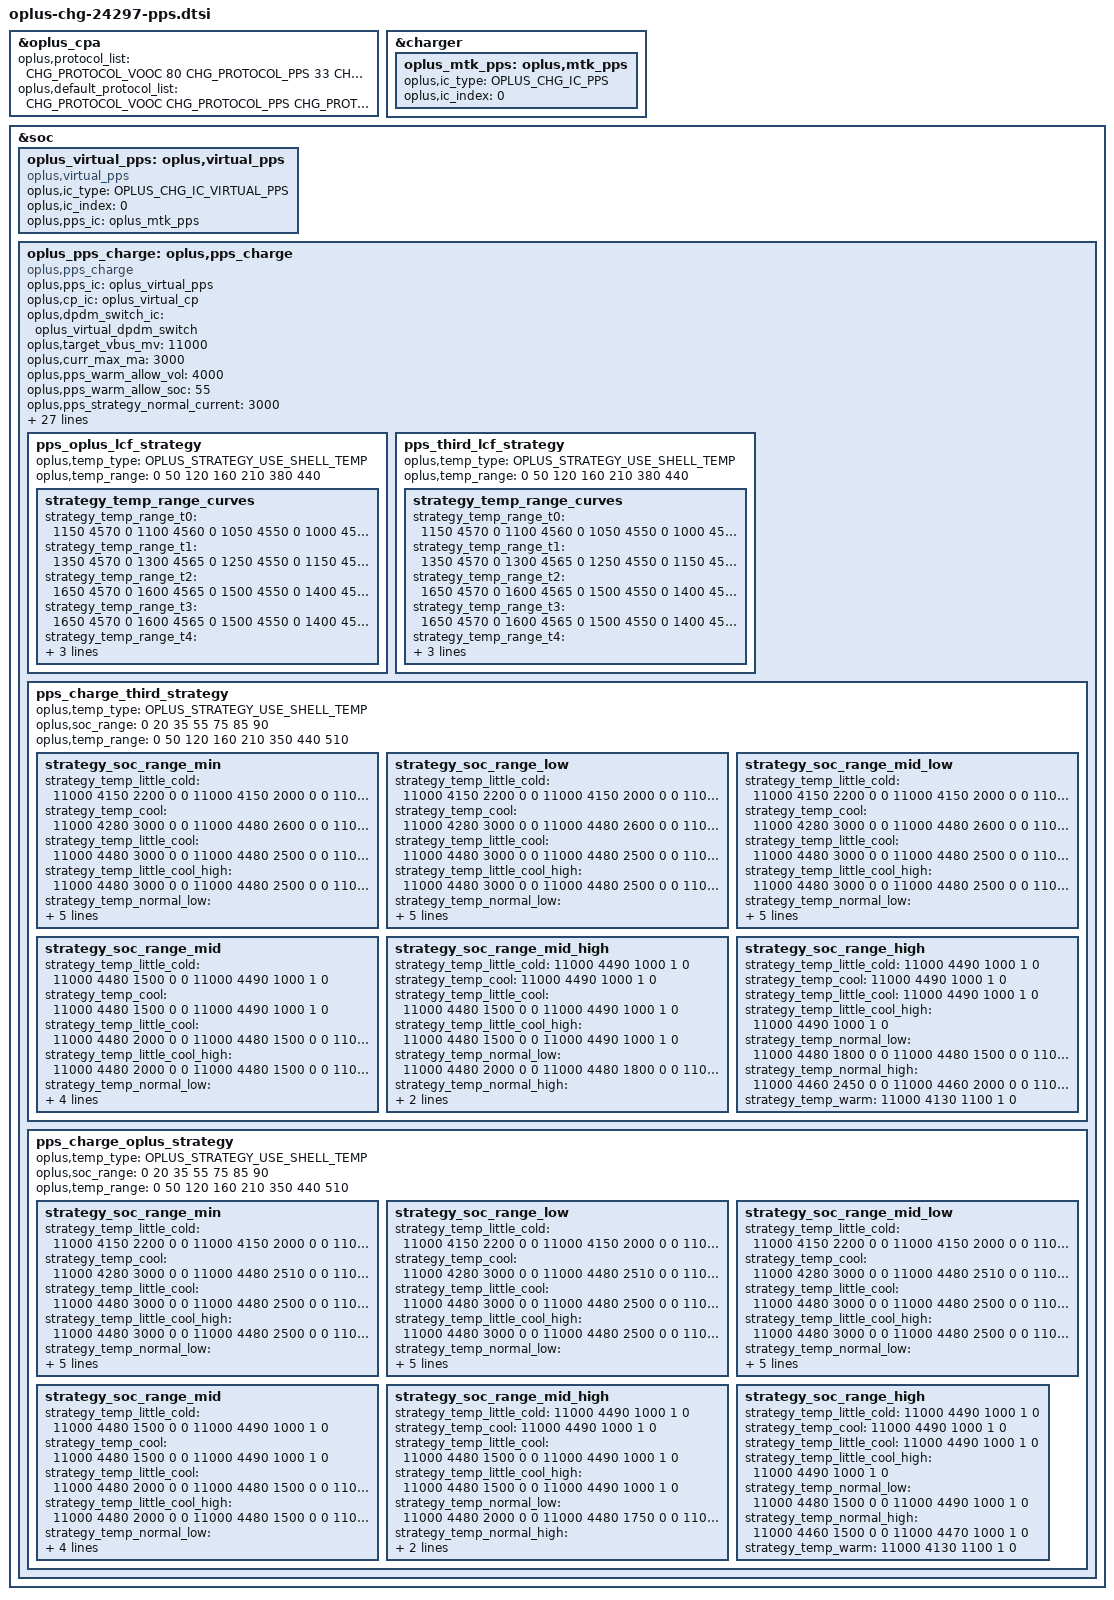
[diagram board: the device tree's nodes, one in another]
//ifdef OPLUS_FEATURE_CHG_BASIC
&oplus_cpa {
	oplus,protocol_list = <CHG_PROTOCOL_VOOC 80
			       CHG_PROTOCOL_PPS 33
			       CHG_PROTOCOL_PD 18
			       CHG_PROTOCOL_QC 18>;
	oplus,default_protocol_list = <CHG_PROTOCOL_VOOC
				       CHG_PROTOCOL_PPS
				       CHG_PROTOCOL_PD>;
};

&charger {
	oplus_mtk_pps: oplus,mtk_pps {
		oplus,ic_type = <OPLUS_CHG_IC_PPS>;
		oplus,ic_index = <0>;
	};
};
&soc {
	oplus_virtual_pps: oplus,virtual_pps {
		compatible = "oplus,virtual_pps";

		oplus,ic_type = <OPLUS_CHG_IC_VIRTUAL_PPS>;
		oplus,ic_index = <0>;
		oplus,pps_ic = <&oplus_mtk_pps>;
	};
	oplus_pps_charge: oplus,pps_charge {
		compatible = "oplus,pps_charge";
		oplus,pps_ic = <&oplus_virtual_pps>;
		oplus,cp_ic = <&oplus_virtual_cp>;
		oplus,dpdm_switch_ic = <&oplus_virtual_dpdm_switch>;

		oplus,target_vbus_mv = <11000>;
		oplus,curr_max_ma = <3000>;

		oplus,pps_warm_allow_vol = <4000>;
		oplus,pps_warm_allow_soc = <55>;
		oplus,pps_strategy_normal_current = <3000>;
		oplus,pps_over_high_or_low_current = <3000>;
		oplus,pps_timeout_third = <17563>;
		oplus,pps_timeout_oplus = <17563>;
		oplus,pps_ibat_over_third = <7400>;
		oplus,pps_ibat_over_oplus = <7400>;
		oplus,pps_full_cool_sw_vbat = <4490>;
		oplus,pps_full_normal_sw_vbat = <4490>;
		oplus,pps_full_normal_hw_vbat = <4500>;
		oplus,pps_full_ffc_vbat = <4500>;
		oplus,pps_full_warm_vbat = <4130>;
		oplus,pps_full_cool_sw_vbat_third = <4490>;
		oplus,pps_full_normal_sw_vbat_third= <4490>;
		oplus,pps_full_normal_hw_vbat_third = <4500>;
		oplus,pps_current_change_timeout = <100>;
		oplus,curve_strategy_name = "pps_ufcs_curve_v2";
		oplus,pps_strategy_batt_high_temp = <410 420 430 400 410 420>;
		oplus,pps_strategy_high_current = <3000 2000 2000 3000 3000 3000>;
		oplus,pps_little_cool_high_temp = <210>;
		oplus,pps_charge_strategy_soc = <0 20 35 55 75 85 90>;
		oplus,pps_charge_strategy_temp = <0 50 120 160 350 440 530>;

		oplus,plc_strategy-data = <&cp_2t1_simple_strategy>;
		oplus,plc_strategy-names = "default";

		pps_oplus_lcf_strategy {
			oplus,temp_type = <OPLUS_STRATEGY_USE_SHELL_TEMP>;
			oplus,temp_range = <0 50 120 160 210 380 440>;

			strategy_temp_range_curves {
				strategy_temp_range_t0 =	<1150 4570 0
								 1100 4560 0
								 1050 4550 0
								 1000 4540 0
								 950 4530 1>;
				strategy_temp_range_t1 =	<1350 4570 0
								 1300 4565 0
								 1250 4550 0
								 1150 4540 0
								 1050 4530 1>;
				strategy_temp_range_t2 =	<1650 4570 0
								 1600 4565 0
								 1500 4550 0
								 1400 4540 0
								 1250 4530 1>;
				strategy_temp_range_t3 =	<1650 4570 0
								 1600 4565 0
								 1500 4550 0
								 1400 4540 0
								 1250 4530 1>;
				strategy_temp_range_t4 =	<3250 4550 0
								 3000 4520 0
								 2300 4520 0
								 1600 4500 0
								 1000 4480 1>;
				strategy_temp_range_t5 =	<4600 4534 0
								 4300 4520 0
								 3200 4500 0
								 2100 4480 0
								 1000 4470 1>;
			};
		};

		pps_third_lcf_strategy {
			oplus,temp_type = <OPLUS_STRATEGY_USE_SHELL_TEMP>;
			oplus,temp_range = <0 50 120 160 210 380 440>;

			strategy_temp_range_curves {
				strategy_temp_range_t0 =	<1150 4570 0
								 1100 4560 0
								 1050 4550 0
								 1000 4540 0
								 950 4530 1>;
				strategy_temp_range_t1 =	<1350 4570 0
								 1300 4565 0
								 1250 4550 0
								 1150 4540 0
								 1050 4530 1>;
				strategy_temp_range_t2 =	<1650 4570 0
								 1600 4565 0
								 1500 4550 0
								 1400 4540 0
								 1250 4530 1>;
				strategy_temp_range_t3 =	<1650 4570 0
								 1600 4565 0
								 1500 4550 0
								 1400 4540 0
								 1250 4530 1>;
				strategy_temp_range_t4 =	<3250 4550 0
								 3000 4520 0
								 2300 4520 0
								 1600 4500 0
								 1000 4480 1>;
				strategy_temp_range_t5 =	<4600 4534 0
								 4300 4520 0
								 3200 4500 0
								 2100 4480 0
								 1000 4470 1>;
			};
		};

		pps_charge_third_strategy {
			oplus,temp_type = <OPLUS_STRATEGY_USE_SHELL_TEMP>;
			oplus,soc_range = <0 20 35 55 75 85 90>;
			oplus,temp_range = <0 50 120 160 210 350 440 510>;

			strategy_soc_range_min {
				strategy_temp_little_cold =	<11000 4150 2200 0 0
								11000 4150 2000 0 0
								11000 4480 1550 0 0
								11000 4480 1500 0 0
								11000 4490 1000 1 0>;
				strategy_temp_cool =		<11000 4280 3000 0 0
								11000 4480 2600 0 0
								11000 4480 2500 0 0
								11000 4480 2000 0 0
								11000 4480 1500 0 0
								11000 4490 1000 1 0>;
				strategy_temp_little_cool =	<11000 4480 3000 0 0
								11000 4480 2500 0 0
								11000 4480 2000 0 0
								11000 4480 1500 0 0
								11000 4490 1000 1 0>;
				strategy_temp_little_cool_high =	<11000 4480 3000 0 0
								11000 4480 2500 0 0
								11000 4480 2000 0 0
								11000 4480 1500 0 0
								11000 4490 1000 1 0>;
				strategy_temp_normal_low =	<11000 4480 3000 0 0
								11000 4480 2500 0 0
								11000 4480 2000 0 0
								11000 4480 1800 0 0
								11000 4480 1500 0 0
								11000 4490 1000 1 0>;
				strategy_temp_normal_high =	<11000 4460 3000 0 0
								11000 4460 2500 0 0
								11000 4460 2450 0 0
								11000 4460 2000 0 0
								11000 4460 1500 0 0
								11000 4470 1000 1 0>;
				strategy_temp_warm =		<11000 4120 1850 0 0
								11000 4120 1500 0 0
								11000 4130 1000 1 0>;
			};
			strategy_soc_range_low {
				strategy_temp_little_cold =	<11000 4150 2200 0 0
								11000 4150 2000 0 0
								11000 4480 1550 0 0
								11000 4480 1500 0 0
								11000 4490 1000 1 0>;
				strategy_temp_cool =		<11000 4280 3000 0 0
								11000 4480 2600 0 0
								11000 4480 2500 0 0
								11000 4480 2000 0 0
								11000 4480 1500 0 0
								11000 4490 1000 1 0>;
				strategy_temp_little_cool =	<11000 4480 3000 0 0
								11000 4480 2500 0 0
								11000 4480 2000 0 0
								11000 4480 1500 0 0
								11000 4490 1000 1 0>;
				strategy_temp_little_cool_high =	<11000 4480 3000 0 0
								11000 4480 2500 0 0
								11000 4480 2000 0 0
								11000 4480 1500 0 0
								11000 4490 1000 1 0>;
				strategy_temp_normal_low =	<11000 4480 3000 0 0
								11000 4480 2500 0 0
								11000 4480 2000 0 0
								11000 4480 1800 0 0
								11000 4480 1500 0 0
								11000 4490 1000 1 0>;
				strategy_temp_normal_high =	<11000 4460 3000 0 0
								11000 4460 2500 0 0
								11000 4460 2450 0 0
								11000 4460 2000 0 0
								11000 4460 1500 0 0
								11000 4470 1000 1 0>;
				strategy_temp_warm =		<11000 4120 1850 0 0
								11000 4120 1500 0 0
								11000 4130 1000 1 0>;
			};
			strategy_soc_range_mid_low {
				strategy_temp_little_cold =	<11000 4150 2200 0 0
								11000 4150 2000 0 0
								11000 4480 1550 0 0
								11000 4480 1500 0 0
								11000 4490 1000 1 0>;
				strategy_temp_cool =		<11000 4280 3000 0 0
								11000 4480 2600 0 0
								11000 4480 2500 0 0
								11000 4480 2000 0 0
								11000 4480 1500 0 0
								11000 4490 1000 1 0>;
				strategy_temp_little_cool =	<11000 4480 3000 0 0
								11000 4480 2500 0 0
								11000 4480 2000 0 0
								11000 4480 1500 0 0
								11000 4490 1000 1 0>;
				strategy_temp_little_cool_high =	<11000 4480 3000 0 0
								11000 4480 2500 0 0
								11000 4480 2000 0 0
								11000 4480 1500 0 0
								11000 4490 1000 1 0>;
				strategy_temp_normal_low =	<11000 4480 3000 0 0
								11000 4480 2500 0 0
								11000 4480 2000 0 0
								11000 4480 1800 0 0
								11000 4480 1500 0 0
								11000 4490 1000 1 0>;
				strategy_temp_normal_high =	<11000 4460 3000 0 0
								11000 4460 2500 0 0
								11000 4460 2450 0 0
								11000 4460 2000 0 0
								11000 4460 1500 0 0
								11000 4470 1000 1 0>;
				strategy_temp_warm =		<11000 4120 1850 0 0
								11000 4120 1500 0 0
								11000 4130 1000 1 0>;
			};
			strategy_soc_range_mid {
				strategy_temp_little_cold =	<11000 4480 1500 0 0
								11000 4490 1000 1 0>;
				strategy_temp_cool =		<11000 4480 1500 0 0
								11000 4490 1000 1 0>;
				strategy_temp_little_cool =	<11000 4480 2000 0 0
								11000 4480 1500 0 0
								11000 4490 1000 1 0>;
				strategy_temp_little_cool_high =	<11000 4480 2000 0 0
								11000 4480 1500 0 0
								11000 4490 1000 1 0>;
				strategy_temp_normal_low =	<11000 4480 2500 0 0
								11000 4480 2000 0 0
								11000 4480 1800 0 0
								11000 4480 1500 0 0
								11000 4490 1000 1 0>;
				strategy_temp_normal_high =	<11000 4460 3000 0 0
								11000 4460 2500 0 0
								11000 4460 2450 0 0
								11000 4460 2000 0 0
								11000 4460 1500 0 0
								11000 4470 1000 1 0>;
				strategy_temp_warm =		<11000 4130 1100 1 0>;
			};
			strategy_soc_range_mid_high {
				strategy_temp_little_cold =	<11000 4490 1000 1 0>;
				strategy_temp_cool =		<11000 4490 1000 1 0>;
				strategy_temp_little_cool =	<11000 4480 1500 0 0
								11000 4490 1000 1 0>;
				strategy_temp_little_cool_high =	<11000 4480 1500 0 0
								11000 4490 1000 1 0>;
				strategy_temp_normal_low =	<11000 4480 2000 0 0
								11000 4480 1800 0 0
								11000 4480 1500 0 0
								11000 4490 1000 1 0>;
				strategy_temp_normal_high =	<11000 4460 2500 0 0
								11000 4460 2450 0 0
								11000 4460 2000 0 0
								11000 4460 1500 0 0
								11000 4470 1000 1 0>;
				strategy_temp_warm =		<11000 4130 1100 1 0>;
			};
			strategy_soc_range_high {
				strategy_temp_little_cold =	<11000 4490 1000 1 0>;
				strategy_temp_cool =		<11000 4490 1000 1 0>;
				strategy_temp_little_cool =	<11000 4490 1000 1 0>;
				strategy_temp_little_cool_high =	<11000 4490 1000 1 0>;
				strategy_temp_normal_low =	<11000 4480 1800 0 0
								11000 4480 1500 0 0
								11000 4490 1000 1 0>;
				strategy_temp_normal_high =	<11000 4460 2450 0 0
								11000 4460 2000 0 0
								11000 4460 1500 0 0
								11000 4470 1000 1 0>;
				strategy_temp_warm =		<11000 4130 1100 1 0>;
			};
		};

		pps_charge_oplus_strategy {
			oplus,temp_type = <OPLUS_STRATEGY_USE_SHELL_TEMP>;
			oplus,soc_range = <0 20 35 55 75 85 90>;
			oplus,temp_range = <0 50 120 160 210 350 440 510>;

			strategy_soc_range_min {
				strategy_temp_little_cold =	<11000 4150 2200 0 0
								11000 4150 2000 0 0
								11000 4480 1550 0 0
								11000 4480 1500 0 0
								11000 4490 1000 1 0>;
				strategy_temp_cool =		<11000 4280 3000 0 0
								11000 4480 2510 0 0
								11000 4480 2500 0 0
								11000 4480 2000 0 0
								11000 4480 1500 0 0
								11000 4490 1000 1 0>;
				strategy_temp_little_cool =	<11000 4480 3000 0 0
								11000 4480 2500 0 0
								11000 4480 2000 0 0
								11000 4480 1500 0 0
								11000 4490 1000 1 0>;
				strategy_temp_little_cool_high =	<11000 4480 3000 0 0
								11000 4480 2500 0 0
								11000 4480 2000 0 0
								11000 4480 1500 0 0
								11000 4490 1000 1 0>;
				strategy_temp_normal_low =	<11000 4480 3000 0 0
								11000 4480 2500 0 0
								11000 4480 2000 0 0
								11000 4480 1750 0 0
								11000 4480 1500 0 0
								11000 4490 1000 1 0>;
				strategy_temp_normal_high =	<11000 4460 3000 0 0
								11000 4460 2500 0 0
								11000 4460 2400 0 0
								11000 4460 2000 0 0
								11000 4460 1500 0 0
								11000 4470 1000 1 0>;
				strategy_temp_warm =		<11000 4120 1850 0 0
								11000 4120 1500 0 0
								11000 4130 1000 1 0>;
			};
			strategy_soc_range_low {
				strategy_temp_little_cold =	<11000 4150 2200 0 0
								11000 4150 2000 0 0
								11000 4480 1550 0 0
								11000 4480 1500 0 0
								11000 4490 1000 1 0>;
				strategy_temp_cool =		<11000 4280 3000 0 0
								11000 4480 2510 0 0
								11000 4480 2500 0 0
								11000 4480 2000 0 0
								11000 4480 1500 0 0
								11000 4490 1000 1 0>;
				strategy_temp_little_cool =	<11000 4480 3000 0 0
								11000 4480 2500 0 0
								11000 4480 2000 0 0
								11000 4480 1500 0 0
								11000 4490 1000 1 0>;
				strategy_temp_little_cool_high =	<11000 4480 3000 0 0
								11000 4480 2500 0 0
								11000 4480 2000 0 0
								11000 4480 1500 0 0
								11000 4490 1000 1 0>;
				strategy_temp_normal_low =	<11000 4480 3000 0 0
								11000 4480 2500 0 0
								11000 4480 2000 0 0
								11000 4480 1750 0 0
								11000 4480 1500 0 0
								11000 4490 1000 1 0>;
				strategy_temp_normal_high =	<11000 4460 3000 0 0
								11000 4460 2500 0 0
								11000 4460 2400 0 0
								11000 4460 2000 0 0
								11000 4460 1500 0 0
								11000 4470 1000 1 0>;
				strategy_temp_warm =		<11000 4120 1850 0 0
								11000 4120 1500 0 0
								11000 4130 1000 1 0>;
			};
			strategy_soc_range_mid_low {
				strategy_temp_little_cold =	<11000 4150 2200 0 0
								11000 4150 2000 0 0
								11000 4480 1550 0 0
								11000 4480 1500 0 0
								11000 4490 1000 1 0>;
				strategy_temp_cool =		<11000 4280 3000 0 0
								11000 4480 2510 0 0
								11000 4480 2500 0 0
								11000 4480 2000 0 0
								11000 4480 1500 0 0
								11000 4490 1000 1 0>;
				strategy_temp_little_cool =	<11000 4480 3000 0 0
								11000 4480 2500 0 0
								11000 4480 2000 0 0
								11000 4480 1500 0 0
								11000 4490 1000 1 0>;
				strategy_temp_little_cool_high =	<11000 4480 3000 0 0
								11000 4480 2500 0 0
								11000 4480 2000 0 0
								11000 4480 1500 0 0
								11000 4490 1000 1 0>;
				strategy_temp_normal_low =	<11000 4480 3000 0 0
								11000 4480 2500 0 0
								11000 4480 2000 0 0
								11000 4480 1750 0 0
								11000 4480 1500 0 0
								11000 4490 1000 1 0>;
				strategy_temp_normal_high =	<11000 4460 3000 0 0
								11000 4460 2500 0 0
								11000 4460 2400 0 0
								11000 4460 2000 0 0
								11000 4460 1500 0 0
								11000 4470 1000 1 0>;
				strategy_temp_warm =		<11000 4120 1850 0 0
								11000 4120 1500 0 0
								11000 4130 1000 1 0>;
			};
			strategy_soc_range_mid {
				strategy_temp_little_cold =	<11000 4480 1500 0 0
								11000 4490 1000 1 0>;
				strategy_temp_cool =		<11000 4480 1500 0 0
								11000 4490 1000 1 0>;
				strategy_temp_little_cool =	<11000 4480 2000 0 0
								11000 4480 1500 0 0
								11000 4490 1000 1 0>;
				strategy_temp_little_cool_high =	<11000 4480 2000 0 0
								11000 4480 1500 0 0
								11000 4490 1000 1 0>;
				strategy_temp_normal_low =	<11000 4480 2500 0 0
								11000 4480 2000 0 0
								11000 4480 1750 0 0
								11000 4480 1500 0 0
								11000 4490 1000 1 0>;
				strategy_temp_normal_high =	<11000 4460 3000 0 0
								11000 4460 2500 0 0
								11000 4460 2400 0 0
								11000 4460 2000 0 0
								11000 4460 1500 0 0
								11000 4470 1000 1 0>;
				strategy_temp_warm =		<11000 4130 1100 1 0>;
			};
			strategy_soc_range_mid_high {
				strategy_temp_little_cold =	<11000 4490 1000 1 0>;
				strategy_temp_cool =		<11000 4490 1000 1 0>;
				strategy_temp_little_cool =	<11000 4480 1500 0 0
								11000 4490 1000 1 0>;
				strategy_temp_little_cool_high =	<11000 4480 1500 0 0
								11000 4490 1000 1 0>;
				strategy_temp_normal_low =	<11000 4480 2000 0 0
								11000 4480 1750 0 0
								11000 4480 1500 0 0
								11000 4490 1000 1 0>;
				strategy_temp_normal_high =	<11000 4460 2500 0 0
								11000 4460 2400 0 0
								11000 4460 2000 0 0
								11000 4460 1500 0 0
								11000 4470 1000 1 0>;
				strategy_temp_warm =		<11000 4130 1100 1 0>;
			};
			strategy_soc_range_high {
				strategy_temp_little_cold =	<11000 4490 1000 1 0>;
				strategy_temp_cool =		<11000 4490 1000 1 0>;
				strategy_temp_little_cool =	<11000 4490 1000 1 0>;
				strategy_temp_little_cool_high =	<11000 4490 1000 1 0>;
				strategy_temp_normal_low =	<11000 4480 1500 0 0
								11000 4490 1000 1 0>;
				strategy_temp_normal_high =	<11000 4460 1500 0 0
								11000 4470 1000 1 0>;
				strategy_temp_warm =		<11000 4130 1100 1 0>;
			};
		};
	};
};
//#endif OPLUS_FEATURE_CHG_BASIC
